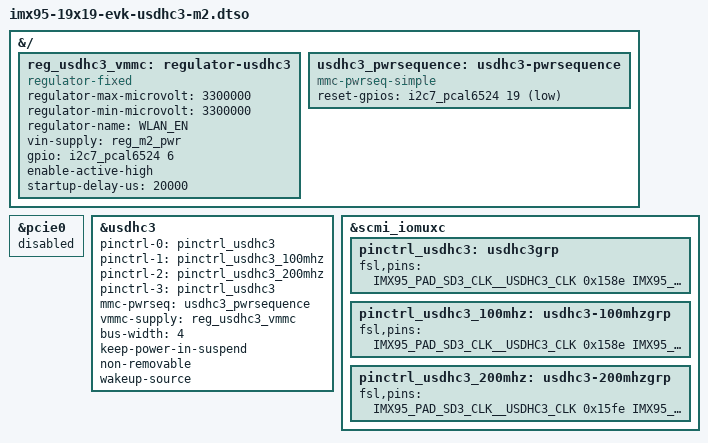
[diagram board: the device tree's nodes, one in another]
// SPDX-License-Identifier: (GPL-2.0+ OR MIT)
/*
 * Copyright 2026 NXP
 */

/dts-v1/;
/plugin/;

#include <dt-bindings/gpio/gpio.h>
#include "imx95-pinfunc.h"
#include "imx95-clock.h"

&{/} {
	reg_usdhc3_vmmc: regulator-usdhc3 {
		compatible = "regulator-fixed";
		regulator-max-microvolt = <3300000>;
		regulator-min-microvolt = <3300000>;
		regulator-name = "WLAN_EN";
		vin-supply = <&reg_m2_pwr>;
		gpio = <&i2c7_pcal6524 6 GPIO_ACTIVE_HIGH>;
		enable-active-high;
		/*
		 * IW612 wifi chip needs more delay than other wifi chips to complete
		 * the host interface initialization after power up, otherwise the
		 * internal state of IW612 may be unstable, resulting in the failure of
		 * the SDIO3.0 switch voltage.
		 */
		startup-delay-us = <20000>;
	};

	usdhc3_pwrsequence: usdhc3-pwrsequence {
		compatible = "mmc-pwrseq-simple";
		reset-gpios = <&i2c7_pcal6524 19 GPIO_ACTIVE_LOW>;
	};
};

&pcie0 {
	status = "disabled";
};

&usdhc3 {
	pinctrl-names = "default", "state_100mhz", "state_200mhz", "sleep";
	pinctrl-0 = <&pinctrl_usdhc3>;
	pinctrl-1 = <&pinctrl_usdhc3_100mhz>;
	pinctrl-2 = <&pinctrl_usdhc3_200mhz>;
	pinctrl-3 = <&pinctrl_usdhc3>;
	mmc-pwrseq = <&usdhc3_pwrsequence>;
	vmmc-supply = <&reg_usdhc3_vmmc>;
	bus-width = <4>;
	keep-power-in-suspend;
	non-removable;
	wakeup-source;
	status = "okay";
};

&scmi_iomuxc {
	pinctrl_usdhc3: usdhc3grp {
		fsl,pins = <
			IMX95_PAD_SD3_CLK__USDHC3_CLK				0x158e
			IMX95_PAD_SD3_CMD__USDHC3_CMD				0x138e
			IMX95_PAD_SD3_DATA0__USDHC3_DATA0			0x138e
			IMX95_PAD_SD3_DATA1__USDHC3_DATA1			0x138e
			IMX95_PAD_SD3_DATA2__USDHC3_DATA2			0x138e
			IMX95_PAD_SD3_DATA3__USDHC3_DATA3			0x138e
		>;
	};

	pinctrl_usdhc3_100mhz: usdhc3-100mhzgrp {
		fsl,pins = <
			IMX95_PAD_SD3_CLK__USDHC3_CLK				0x158e
			IMX95_PAD_SD3_CMD__USDHC3_CMD				0x138e
			IMX95_PAD_SD3_DATA0__USDHC3_DATA0			0x138e
			IMX95_PAD_SD3_DATA1__USDHC3_DATA1			0x138e
			IMX95_PAD_SD3_DATA2__USDHC3_DATA2			0x138e
			IMX95_PAD_SD3_DATA3__USDHC3_DATA3			0x138e
		>;
	};

	pinctrl_usdhc3_200mhz: usdhc3-200mhzgrp {
		fsl,pins = <
			IMX95_PAD_SD3_CLK__USDHC3_CLK				0x15fe
			IMX95_PAD_SD3_CMD__USDHC3_CMD				0x13fe
			IMX95_PAD_SD3_DATA0__USDHC3_DATA0			0x13fe
			IMX95_PAD_SD3_DATA1__USDHC3_DATA1			0x13fe
			IMX95_PAD_SD3_DATA2__USDHC3_DATA2			0x13fe
			IMX95_PAD_SD3_DATA3__USDHC3_DATA3			0x13fe
		>;
	};
};
